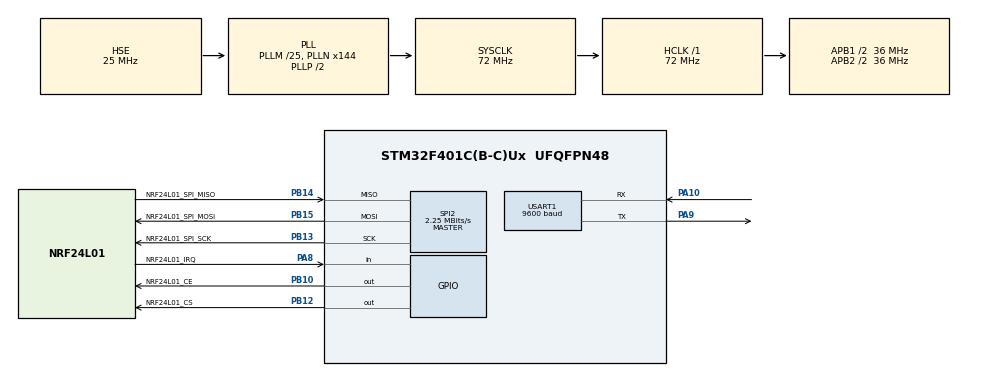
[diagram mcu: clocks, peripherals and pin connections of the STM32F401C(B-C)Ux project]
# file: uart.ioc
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Mcu.Family=STM32F4
Mcu.Name=STM32F401C(B-C)Ux
Mcu.Package=UFQFPN48
NVIC.PriorityGroup=NVIC_PRIORITYGROUP_4
PA10.Mode=Asynchronous
PA10.Signal=USART1_RX
PA8.GPIO_Label=NRF24L01_IRQ
PA8.Signal=GPIO_Input
PA9.Mode=Asynchronous
PA9.Signal=USART1_TX
PB10.GPIO_Label=NRF24L01_CE
PB10.Signal=GPIO_Output
PB12.GPIO_Label=NRF24L01_CS
PB12.Signal=GPIO_Output
PB13.GPIO_Label=NRF24L01_SPI_SCK
PB13.Mode=Full_Duplex_Master
PB13.Signal=SPI2_SCK
PB14.GPIO_Label=NRF24L01_SPI_MISO
PB14.Mode=Full_Duplex_Master
PB14.Signal=SPI2_MISO
PB15.GPIO_Label=NRF24L01_SPI_MOSI
PB15.Mode=Full_Duplex_Master
PB15.Signal=SPI2_MOSI
PH0\ -\ OSC_IN.Mode=HSE-External-Oscillator
PH0\ -\ OSC_IN.Signal=RCC_OSC_IN
PH1\ -\ OSC_OUT.Mode=HSE-External-Oscillator
PH1\ -\ OSC_OUT.Signal=RCC_OSC_OUT
ProjectManager.HeapSize=0x200
ProjectManager.StackSize=0x400
ProjectManager.TargetToolchain=Makefile
RCC.48MHZClocksFreq_Value=36000000
RCC.AHBFreq_Value=72000000
RCC.APB1CLKDivider=RCC_HCLK_DIV2
RCC.APB1Freq_Value=36000000
RCC.APB1TimFreq_Value=72000000
RCC.APB2CLKDivider=RCC_HCLK_DIV2
RCC.APB2Freq_Value=36000000
RCC.APB2TimFreq_Value=72000000
RCC.CortexFreq_Value=72000000
RCC.HCLKFreq_Value=72000000
RCC.HSE_VALUE=25000000
RCC.HSI_VALUE=16000000
RCC.LSE_VALUE=32768
RCC.PLLM=25
RCC.PLLN=144
RCC.PLLSourceVirtual=RCC_PLLSOURCE_HSE
RCC.SYSCLKFreq_VALUE=72000000
RCC.SYSCLKSource=RCC_SYSCLKSOURCE_PLLCLK
RCC.VCOOutputFreq_Value=144000000
SPI2.BaudRatePrescaler=SPI_BAUDRATEPRESCALER_16
SPI2.CalculateBaudRate=2.25 MBits/s
SPI2.Direction=SPI_DIRECTION_2LINES
SPI2.Mode=SPI_MODE_MASTER
SPI2.VirtualType=VM_MASTER
USART1.BaudRate=9600
USART1.VirtualMode=VM_ASYNC
board=custom

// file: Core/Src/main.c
/* USER CODE BEGIN Header */
/**
  ******************************************************************************
  * @file           : main.c
  * @brief          : Main program body
  ******************************************************************************
  * @attention
  *
  * <h2><center>&copy; Copyright (c) 2021 STMicroelectronics.
  * All rights reserved.</center></h2>
  *
  * This software component is licensed by ST under BSD 3-Clause license,
  * the "License"; You may not use this file except in compliance with the
  * License. You may obtain a copy of the License at:
  *                        opensource.org/licenses/BSD-3-Clause
  *
  ******************************************************************************
  */
/* USER CODE END Header */
#include "main.h"
#include "spi.h"
#include "usart.h"
#include "gpio.h"

/* USER CODE BEGIN Includes */
#include "NRF24L01.h"

/* USER CODE END Includes */

/* USER CODE BEGIN PV */
uint8_t rx_buf[33];
uint8_t slave_id = 3;   //0~3
/* USER CODE END PV */

void SystemClock_Config(void);

int main(void)
{

  /* MCU Configuration--------------------------------------------------------*/

  /* Reset of all peripherals, Initializes the Flash interface and the Systick. */
  HAL_Init();

  /* Configure the system clock */
  SystemClock_Config();

  /* Initialize all configured peripherals */
  MX_GPIO_Init();
  MX_USART1_UART_Init();
  MX_SPI2_Init();
  /* USER CODE BEGIN 2 */

	while(NRF24L01_Check())
	{
    printf("Can not find NRF24L01\r\n");
		HAL_Delay(1000);
	}
  printf("NRF24L01 connect sucessfully\r\n");
  NRF24L01_RX_Mode(slave_id);

  /* USER CODE END 2 */

  /* Infinite loop */
  while (1)
  {

    /* USER CODE BEGIN 3 */

    if(NRF24L01_RxPacket(rx_buf)==1)
    {
      printf("Address %d RX Success:%s.\r\n",slave_id,rx_buf);
    }
    else
    {
      printf("Address %d RX Nothing.\r\n",slave_id);
    }

  }
  /* USER CODE END 3 */
}

void SystemClock_Config(void)
{
  RCC_OscInitTypeDef RCC_OscInitStruct = {0};
  RCC_ClkInitTypeDef RCC_ClkInitStruct = {0};

  /** Configure the main internal regulator output voltage
  */
  __HAL_RCC_PWR_CLK_ENABLE();
  __HAL_PWR_VOLTAGESCALING_CONFIG(PWR_REGULATOR_VOLTAGE_SCALE2);
  /** Initializes the RCC Oscillators according to the specified parameters
  * in the RCC_OscInitTypeDef structure.
  */
  RCC_OscInitStruct.OscillatorType = RCC_OSCILLATORTYPE_HSE;
  RCC_OscInitStruct.HSEState = RCC_HSE_ON;
  RCC_OscInitStruct.PLL.PLLState = RCC_PLL_ON;
  RCC_OscInitStruct.PLL.PLLSource = RCC_PLLSOURCE_HSE;
  RCC_OscInitStruct.PLL.PLLM = 25;
  RCC_OscInitStruct.PLL.PLLN = 144;
  RCC_OscInitStruct.PLL.PLLP = RCC_PLLP_DIV2;
  RCC_OscInitStruct.PLL.PLLQ = 4;
  if (HAL_RCC_OscConfig(&RCC_OscInitStruct) != HAL_OK)
  {
    Error_Handler();
  }
  /** Initializes the CPU, AHB and APB buses clocks
  */
  RCC_ClkInitStruct.ClockType = RCC_CLOCKTYPE_HCLK|RCC_CLOCKTYPE_SYSCLK
                              |RCC_CLOCKTYPE_PCLK1|RCC_CLOCKTYPE_PCLK2;
  RCC_ClkInitStruct.SYSCLKSource = RCC_SYSCLKSOURCE_PLLCLK;
  RCC_ClkInitStruct.AHBCLKDivider = RCC_SYSCLK_DIV1;
  RCC_ClkInitStruct.APB1CLKDivider = RCC_HCLK_DIV2;
  RCC_ClkInitStruct.APB2CLKDivider = RCC_HCLK_DIV2;

  if (HAL_RCC_ClockConfig(&RCC_ClkInitStruct, FLASH_LATENCY_2) != HAL_OK)
  {
    Error_Handler();
  }
}

void Error_Handler(void)
{
  __disable_irq();
  while (1)
  {
  }
}

/************************ (C) COPYRIGHT STMicroelectronics *****END OF FILE****/
